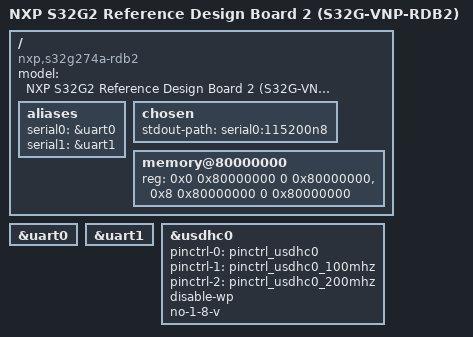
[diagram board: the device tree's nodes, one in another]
// SPDX-License-Identifier: GPL-2.0-or-later OR MIT
/*
 * Copyright (c) 2021 SUSE LLC
 * Copyright 2019-2021, 2024 NXP
 */

/dts-v1/;

#include "s32g2.dtsi"

/ {
	model = "NXP S32G2 Reference Design Board 2 (S32G-VNP-RDB2)";
	compatible = "nxp,s32g274a-rdb2", "nxp,s32g2";

	aliases {
		serial0 = &uart0;
		serial1 = &uart1;
	};

	chosen {
		stdout-path = "serial0:115200n8";
	};

	/* 4GiB RAM */
	memory@80000000 {
		device_type = "memory";
		reg = <0x0 0x80000000 0 0x80000000>,
		      <0x8 0x80000000 0 0x80000000>;
	};
};

/* UART (J2) to Micro USB port */
&uart0 {
	status = "okay";
};

/* UART (J1) to Micro USB port */
&uart1 {
	status = "okay";
};

&usdhc0 {
	pinctrl-names = "default", "state_100mhz", "state_200mhz";
	pinctrl-0 = <&pinctrl_usdhc0>;
	pinctrl-1 = <&pinctrl_usdhc0_100mhz>;
	pinctrl-2 = <&pinctrl_usdhc0_200mhz>;
	disable-wp;
	/* Remove no-1-8-v to enable higher speed modes for SD card.
	 * However, this is not enough to enable HS400 or HS200 modes for eMMC.
	 * In this case, the position of the resistor R797 must be changed
	 * from A to B before removing the property.
	 * If the property is removed without changing the resistor position,
	 * HS*00 may be enabled, but the interface might be unstable because of
	 * the wrong VCCQ voltage applied to the eMMC.
	 */
	no-1-8-v;
	status = "okay";
};
